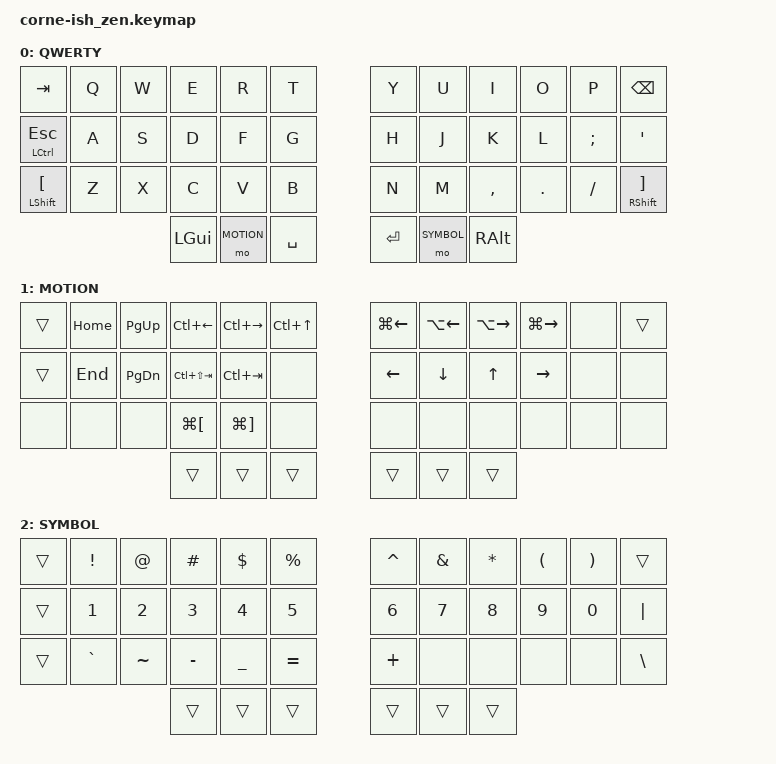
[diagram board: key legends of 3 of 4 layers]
/*
*
* Copyright (c) 2021 Darryl deHaan
* SPDX-License-Identifier: MIT
*
*/

#include <behaviors.dtsi>
#include <dt-bindings/zmk/keys.h>
#include <dt-bindings/zmk/bt.h>

#define QWERTY 0
#define MOTION 1
#define SYMBOL 2
#define ADJUST 3

/ {
        conditional_layers {
                compatible = "zmk,conditional-layers";
                tri_layer {
                        if-layers = <1 2>;
                        then-layer = <3>;
                };
        };
    
        keymap {
                compatible = "zmk,keymap";

                default_layer {
                        label = "QWERTY";
// -----------------------------------------------------------------------------------------
// | TAB       |  Q  |  W  |  E  |  R  |  T  |   |  Y  |  U  |  I  |  O  |  P  | BKSP    |
// | CTRL(ESC) |  A  |  S  |  D  |  F  |  G  |   |  H  |  J  |  K  |  L  |  ;  | '       |
// | SHFT([)   |  Z  |  X  |  C  |  V  |  B  |   |  N  |  M  |  ,  |  .  |  /  | SHFT(]) |
//                         | GUI | NAV | SPC |   | ENT | NUM | ALT |
                        bindings = <
   &kp TAB        &kp Q &kp W &kp E    &kp R      &kp T       &kp Y     &kp U      &kp I     &kp O   &kp P    &kp BSPC
   &mt LCTRL ESC  &kp A &kp S &kp D    &kp F      &kp G       &kp H     &kp J      &kp K     &kp L   &kp SEMI &kp SQT
   &mt LSHFT LBKT &kp Z &kp X &kp C    &kp V      &kp B       &kp N     &kp M      &kp COMMA &kp DOT &kp FSLH &mt RSHFT RBKT
                              &kp LGUI &mo MOTION &kp SPACE   &kp ENTER &mo SYMBOL &kp RALT
                        >;
                };
                
                motion_layer {
                        label = "MOTION";
// -----------------------------------------------------------------------------------------
// |     | HOME | PGUP | CTRL(LFT)| CTRL(RGT)| CTRL(UP)|   | LINE_BEG | PREV_WRD | NEXT_WRD | LINE_END | N/A |     |
// |     | END  | PGDN | PREV_TAB | NEXT_TAB | N/A     |   | LEFT     | DOWN     | UP       | RIGHT    | N/A | N/A |
// | N/A | N/A  | N/A  | BACK     | FWD      | N/A     |   | N/A      | N/A      | N/A      | N/A      | N/A | N/A |
//                     |          |          |         |   |          |          |          |
                        bindings = <
   &trans &kp HOME &kp PG_UP &kp LC(LEFT)    &kp LC(RIGHT) &kp LC(UP)   &kp LG(LEFT) &kp LA(LEFT) &kp LA(RIGHT) &kp LG(RIGHT) &none &trans
   &trans &kp END  &kp PG_DN &kp LC(LS(TAB)) &kp LC(TAB)   &none        &kp LEFT     &kp DOWN     &kp UP        &kp RIGHT     &none &none
   &none  &none    &none     &kp LG(LBKT)    &kp LG(RBKT)  &none        &none        &none        &none         &none         &none &none
                    	     &trans          &trans        &trans       &trans       &trans       &trans 
                        >;
                };

                symbol_layer {
                        label = "SYMBOL";
// -----------------------------------------------------------------------------------------
// |     |  !  |  @  |  #  |  $  |  %  |   |  ^  |  &  |  *  |  (  |  )  |     |
// |     |  1  |  2  |  3  |  4  |  5  |   |  6  |  7  |  8  |  9  |  0  | "|" |
// |     |  `  |  ~  |  -  |  _  |  =  |   |  +  | N/A | N/A | N/A | N/A |  \  |
//                   |     |     |     |   |     |     |     |
                        bindings = <
   &trans &kp EXCL  &kp AT    &kp HASH  &kp DLLR  &kp PRCNT   &kp CARET &kp AMPS &kp STAR &kp LPAR &kp RPAR &trans
   &trans &kp N1    &kp N2    &kp N3    &kp N4    &kp N5      &kp N6    &kp N7   &kp N8   &kp N9   &kp N0   &kp PIPE
   &trans &kp GRAVE &kp TILDE &kp MINUS &kp UNDER &kp EQUAL   &kp PLUS  &none    &none    &none    &none    &kp BSLH
                    	      &trans    &trans    &trans      &trans    &trans   &trans 
                        >;
                };
                
                adjust_layer {
                        label = "ADJUST";
// -----------------------------------------------------------------------------------------
// | N/A | N/A | N/A | N/A | N/A | N/A |   | N/A | VOL_UP | N/A | N/A | N/A | N/A |
// |BTCLR| BT1 | BT2 | BT3 | BT4 | BT5 |   | N/A | VOL_DN | N/A | N/A | N/A | N/A |
// | N/A | N/A | N/A | N/A | N/A | N/A |   | N/A | MUTE   | N/A | N/A | N/A | N/A |
//                   |     |     |     |   |     |        |     |
                        bindings = <
   &none      &none        &none        &none        &none        &none          &none  &kp C_VOL_UP &none &none &none
   &bt BT_CLR &bt BT_SEL 0 &bt BT_SEL 1 &bt BT_SEL 2 &bt BT_SEL 3 &bt BT_SEL 4   &none  &kp C_VOL_DN &none &none &none
   &none      &none        &none        &none        &none        &none          &none  &kp K_MUTE   &none &none &none
                    	                &trans       &trans       &trans         &trans &trans &trans 
                        >;
                };
        };
};
